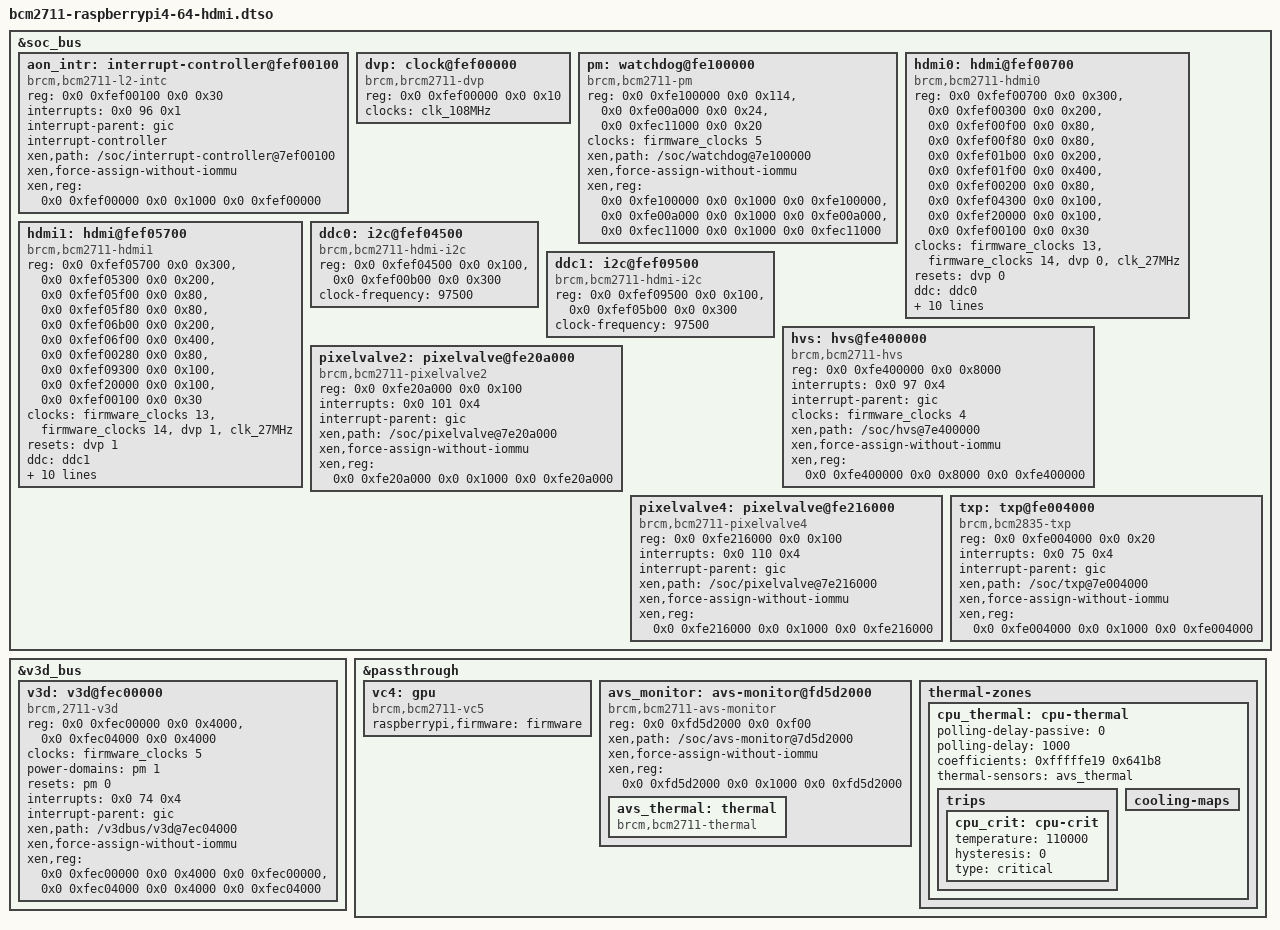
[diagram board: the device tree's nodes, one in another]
/*
 * Copyright (c) 2025 EPAM systems
 *
 * SPDX-License-Identifier: Apache-2.0
 */

/*
 * ============================================================================
 * BCM2711 display / GPU complex for the base DomD partial DT
 * ============================================================================
 * Optional overlay (MACHINE_FEATURES "domd_hdmi") that adds the vc4 display
 * stack to bcm2711-raspberrypi4-64-domd.dts. The SoDeV cockpit does not use it —
 * boot.cmd loads the self-contained bcm2711-raspberrypi4-64-domd-vc4.dtb — but the
 * two files describe the SAME hardware and MUST stay in sync. Treat
 * recipes-guest/domd-vc4/files/bcm2711-raspberrypi4-64-domd-vc4.dts as the
 * reference; its long rationale comments are not duplicated here.
 *
 * Removed versus BCM2712: cpu_l2_irq, disp_intr, bsc_irq, mop, moplet, the
 * BCM2712 IOMMU, dma32/dma40 HDMI audio DMA and the 40-bit 0x10_7c...... bus
 * wrapper. Added/changed: single `aon_intr` L2 controller (GIC SPI 96, EDGE),
 * HVS straight on GIC SPI 97, `txp` for the transposer CRTC, `pm` for V3D's
 * power domain + reset, pixelvalve2/pixelvalve4 as the two HDMI CRTCs, and
 * `brcm,bcm2711-vc5` on a childless /gpu node.
 *
 * Validate with:
 *   The DomD passthrough cross-check <compiled base+overlay> \
 *       --host bcm2711-rpi-4-b.dtb
 * ============================================================================
 */

/dts-v1/;
/plugin/;

&soc_bus {
	/*
	 * Display/HDMI L2 interrupt controller. Owns the 0xfef00000 page, which
	 * also contains dvp, HDMI0's hdmi/dvp/phy/rm/csc blocks, HDMI1's csc and
	 * ddc0's auto-i2c window — so it is the single xen,reg owner for that
	 * page and the one node that needs GIC SPI 96 routed.
	 */
	aon_intr: interrupt-controller@fef00100 {
		compatible = "brcm,bcm2711-l2-intc", "brcm,l2-intc";
		reg = <0x0 0xfef00100 0x0 0x30>;
		interrupts = <0x0 96 0x1>;		/* GIC SPI 96 EDGE_RISING */
		interrupt-parent = <&gic>;
		interrupt-controller;
		#interrupt-cells = <0x1>;
		xen,path = "/soc/interrupt-controller@7ef00100";
		xen,force-assign-without-iommu;
		xen,reg = <0x0 0xfef00000 0x0 0x1000 0x0 0xfef00000>;
		status = "okay";
	};

	/* HDMI audio clock + HDMI resets. Inside aon_intr's page, no IRQ. */
	dvp: clock@fef00000 {
		compatible = "brcm,brcm2711-dvp";
		reg = <0x0 0xfef00000 0x0 0x10>;
		clocks = <&clk_108MHz>;
		#clock-cells = <0x1>;
		#reset-cells = <0x1>;
		status = "okay";
	};

	/* V3D power domain (GRAFX_V3D = 1) + reset (BCM2835_RESET_V3D = 0). */
	pm: watchdog@fe100000 {
		compatible = "brcm,bcm2711-pm", "brcm,bcm2835-pm-wdt";
		#power-domain-cells = <0x1>;
		#reset-cells = <0x1>;
		reg = <0x0 0xfe100000 0x0 0x114>,
		      <0x0 0xfe00a000 0x0 0x24>,
		      <0x0 0xfec11000 0x0 0x20>;
		reg-names = "pm", "asb", "rpivid_asb";
		clocks = <&firmware_clocks 5>;
		clock-names = "v3d";
		xen,path = "/soc/watchdog@7e100000";
		xen,force-assign-without-iommu;
		xen,reg = <0x0 0xfe100000 0x0 0x1000 0x0 0xfe100000>,
			  <0x0 0xfe00a000 0x0 0x1000 0x0 0xfe00a000>,
			  <0x0 0xfec11000 0x0 0x1000 0x0 0xfec11000>;
		status = "okay";
	};

	hdmi0: hdmi@fef00700 {
		compatible = "brcm,bcm2711-hdmi0";
		reg = <0x0 0xfef00700 0x0 0x300>,
		      <0x0 0xfef00300 0x0 0x200>,
		      <0x0 0xfef00f00 0x0 0x80>,
		      <0x0 0xfef00f80 0x0 0x80>,
		      <0x0 0xfef01b00 0x0 0x200>,
		      <0x0 0xfef01f00 0x0 0x400>,
		      <0x0 0xfef00200 0x0 0x80>,
		      <0x0 0xfef04300 0x0 0x100>,
		      <0x0 0xfef20000 0x0 0x100>,
		      <0x0 0xfef00100 0x0 0x30>;
		reg-names = "hdmi", "dvp", "phy", "rm", "packet",
			    "metadata", "csc", "cec", "hd", "intr2";
		clocks = <&firmware_clocks 13>, <&firmware_clocks 14>,
			 <&dvp 0>, <&clk_27MHz>;
		clock-names = "hdmi", "bvb", "audio", "cec";
		resets = <&dvp 0>;
		ddc = <&ddc0>;
		ddc-i2c-bus = <&ddc0>;
		interrupt-parent = <&aon_intr>;
		interrupts = <0>, <1>, <2>, <3>, <4>, <5>;
		interrupt-names = "cec-tx", "cec-rx", "cec-low",
				  "wakeup", "hpd-connected", "hpd-removed";
		wifi-2.4ghz-coexistence;
		xen,path = "/soc/hdmi@7ef00700";
		xen,force-assign-without-iommu;
		/* metadata (0xfef01f00 + 0x400) crosses into 0xfef02000 */
		xen,reg = <0x0 0xfef01000 0x0 0x2000 0x0 0xfef01000>,
			  <0x0 0xfef04000 0x0 0x1000 0x0 0xfef04000>,
			  <0x0 0xfef20000 0x0 0x1000 0x0 0xfef20000>;
		status = "okay";
	};

	hdmi1: hdmi@fef05700 {
		compatible = "brcm,bcm2711-hdmi1";
		reg = <0x0 0xfef05700 0x0 0x300>,
		      <0x0 0xfef05300 0x0 0x200>,
		      <0x0 0xfef05f00 0x0 0x80>,
		      <0x0 0xfef05f80 0x0 0x80>,
		      <0x0 0xfef06b00 0x0 0x200>,
		      <0x0 0xfef06f00 0x0 0x400>,
		      <0x0 0xfef00280 0x0 0x80>,
		      <0x0 0xfef09300 0x0 0x100>,
		      <0x0 0xfef20000 0x0 0x100>,
		      <0x0 0xfef00100 0x0 0x30>;
		reg-names = "hdmi", "dvp", "phy", "rm", "packet",
			    "metadata", "csc", "cec", "hd", "intr2";
		clocks = <&firmware_clocks 13>, <&firmware_clocks 14>,
			 <&dvp 1>, <&clk_27MHz>;
		clock-names = "hdmi", "bvb", "audio", "cec";
		resets = <&dvp 1>;
		ddc = <&ddc1>;
		ddc-i2c-bus = <&ddc1>;
		interrupt-parent = <&aon_intr>;
		interrupts = <8>, <7>, <6>, <9>, <10>, <11>;
		interrupt-names = "cec-tx", "cec-rx", "cec-low",
				  "wakeup", "hpd-connected", "hpd-removed";
		wifi-2.4ghz-coexistence;
		xen,path = "/soc/hdmi@7ef05700";
		xen,force-assign-without-iommu;
		/* hd (0xfef20000) is mapped by hdmi0; do not map it twice */
		xen,reg = <0x0 0xfef05000 0x0 0x1000 0x0 0xfef05000>,
			  <0x0 0xfef06000 0x0 0x2000 0x0 0xfef06000>,
			  <0x0 0xfef09000 0x0 0x1000 0x0 0xfef09000>;
		status = "okay";
	};

	/* DDC: no clocks and no IRQ on BCM2711; both pages already mapped. */
	ddc0: i2c@fef04500 {
		compatible = "brcm,bcm2711-hdmi-i2c";
		reg = <0x0 0xfef04500 0x0 0x100>,
		      <0x0 0xfef00b00 0x0 0x300>;
		reg-names = "bsc", "auto-i2c";
		clock-frequency = <97500>;
		#address-cells = <1>;
		#size-cells = <0>;
		status = "okay";
	};

	ddc1: i2c@fef09500 {
		compatible = "brcm,bcm2711-hdmi-i2c";
		reg = <0x0 0xfef09500 0x0 0x100>,
		      <0x0 0xfef05b00 0x0 0x300>;
		reg-names = "bsc", "auto-i2c";
		clock-frequency = <97500>;
		#address-cells = <1>;
		#size-cells = <0>;
		status = "okay";
	};

	hvs: hvs@fe400000 {
		compatible = "brcm,bcm2711-hvs";
		reg = <0x0 0xfe400000 0x0 0x8000>;
		interrupts = <0x0 97 0x4>;		/* GIC SPI 97, no L2 hop */
		interrupt-parent = <&gic>;
		clocks = <&firmware_clocks 4>;		/* unnamed, as on the host */
		xen,path = "/soc/hvs@7e400000";
		xen,force-assign-without-iommu;
		xen,reg = <0x0 0xfe400000 0x0 0x8000 0x0 0xfe400000>;
		status = "okay";
	};

	pixelvalve2: pixelvalve@fe20a000 {
		compatible = "brcm,bcm2711-pixelvalve2";	/* CRTC for HDMI0 */
		reg = <0x0 0xfe20a000 0x0 0x100>;
		interrupts = <0x0 101 0x4>;
		interrupt-parent = <&gic>;
		xen,path = "/soc/pixelvalve@7e20a000";
		xen,force-assign-without-iommu;
		xen,reg = <0x0 0xfe20a000 0x0 0x1000 0x0 0xfe20a000>;
		status = "okay";
	};

	pixelvalve4: pixelvalve@fe216000 {
		compatible = "brcm,bcm2711-pixelvalve4";	/* CRTC for HDMI1 */
		reg = <0x0 0xfe216000 0x0 0x100>;
		interrupts = <0x0 110 0x4>;
		interrupt-parent = <&gic>;
		xen,path = "/soc/pixelvalve@7e216000";
		xen,force-assign-without-iommu;
		xen,reg = <0x0 0xfe216000 0x0 0x1000 0x0 0xfe216000>;
		status = "okay";
	};

	txp: txp@fe004000 {
		compatible = "brcm,bcm2835-txp";
		reg = <0x0 0xfe004000 0x0 0x20>;
		interrupts = <0x0 75 0x4>;
		interrupt-parent = <&gic>;
		xen,path = "/soc/txp@7e004000";
		xen,force-assign-without-iommu;
		xen,reg = <0x0 0xfe004000 0x0 0x1000 0x0 0xfe004000>;
		status = "okay";
	};
};

&v3d_bus {
	/* Two reg blocks only (hub + core0); "sms" is BCM2712/V3D-7.1. */
	v3d: v3d@fec00000 {
		compatible = "brcm,2711-v3d";
		reg = <0x0 0xfec00000 0x0 0x4000>,
		      <0x0 0xfec04000 0x0 0x4000>;
		reg-names = "hub", "core0";
		clocks = <&firmware_clocks 5>;
		power-domains = <&pm 1>;
		resets = <&pm 0>;
		interrupts = <0x0 74 0x4>;
		interrupt-parent = <&gic>;
		xen,path = "/v3dbus/v3d@7ec04000";
		xen,force-assign-without-iommu;
		xen,reg = <0x0 0xfec00000 0x0 0x4000 0x0 0xfec00000>,
			  <0x0 0xfec04000 0x0 0x4000 0x0 0xfec04000>;
		status = "okay";
	};
};

&passthrough {
	/*
	 * vc4 aggregate. On BCM2711 the host /gpu node is a leaf: vc4's
	 * component collection walks the platform bus by driver, not by child
	 * node. brcm,2711-v3d is NOT in vc4_v3d_dt_match[], so vc4 is
	 * display-only here and drivers/gpu/drm/v3d owns the 3D core.
	 */
	vc4: gpu {
		compatible = "brcm,bcm2711-vc5";
		raspberrypi,firmware = <&firmware>;
		status = "okay";
	};

	avs_monitor: avs-monitor@fd5d2000 {
		compatible = "brcm,bcm2711-avs-monitor", "syscon", "simple-mfd";
		reg = <0x0 0xfd5d2000 0x0 0xf00>;
		xen,path = "/soc/avs-monitor@7d5d2000";
		xen,force-assign-without-iommu;
		xen,reg = <0x0 0xfd5d2000 0x0 0x1000 0x0 0xfd5d2000>;
		status = "okay";

		avs_thermal: thermal {
			compatible = "brcm,bcm2711-thermal";
			#thermal-sensor-cells = <0x0>;
		};
	};

	thermal-zones {
		cpu_thermal: cpu-thermal {
			polling-delay-passive = <0>;
			polling-delay = <1000>;
			coefficients = <0xfffffe19 0x641b8>;	/* <(-487) 410040> */
			thermal-sensors = <&avs_thermal>;

			trips {
				cpu_crit: cpu-crit {
					temperature = <110000>;
					hysteresis = <0>;
					type = "critical";
				};
			};

			cooling-maps {
			};
		};
	};
};
